# A31L12x register map
Vendor: VENDOR ABOV Semiconductor Co., Ltd.; Series: A31L12x; File version: 1.0
CPU: CM0+ r0p1, little endian, no MPU, no FPU, VTOR, 2 interrupt priority bits
Registers are 32-bit, read-write, reset 0x0 unless marked. A register's access mark holds for its fields unless they carry their own. Offsets are from the block's base; [hi:lo] are bit positions; {n}, {i} and the like mark numbered series.

## SCULV — System Control Unit: LVI and LVR
Base 0x40005100
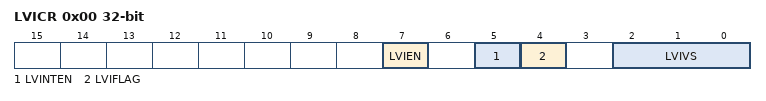
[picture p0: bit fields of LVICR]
0x00 LVICR — Low Voltage Indicator Control Register
  [7] LVIEN — LVI Enable
    0=Disable low voltage indicator; 1=Enable low voltage indicator
  [5] LVINTEN — LVI Interrupt Enable
    0=Disable low voltage indicator interrupt; 1=Enable low voltage indicator interrupt
  [4] LVIFLAG — LVI Interrupt Flag
    0=No request occurred; 1=Request occurred
  [2:0] LVIVS — LVI Voltage Selection
    0=1p75V0 (1.75V); 1=1p75V1 (1.75V); 2=1p90V (1.90V); 3=2p05V (2.05V); 4=2p20V (2.20V); 5=2p35V (2.35V); 6=2p50V (2.50V); 7=2p65V (2.65V)
0x04 LVRCR — Low Voltage Reset Control Register
  [7:0] LVREN — LVR Enable
    85=Disable low voltage reset. (0x55); 0=Enable low voltage reset

## PMU — Power Management Unit
Base 0x40001900
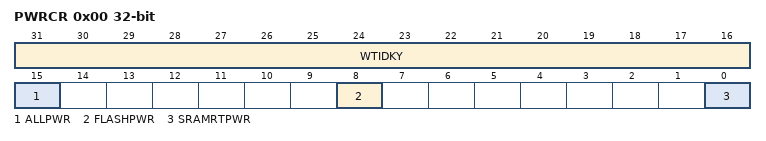
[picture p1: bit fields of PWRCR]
0x00 PWRCR — Power Control Register
  [31:16] WTIDKY wo — Write Identification Key (0x5072)
    0x5072=Value (Key Value (0x5072))
  [15] ALLPWR — All System and Peripheral Except Always-on Regiion Power Control
    0=BySW (Power on/off is controlled by each power control bit); 1=Off (Power off all system and peripheral except always-on region)
  [8] FLASHPWR — Flash Memory Power Control
    0=On (Power On); 1=Off (Power Off)
  [0] SRAMRTPWR — SRAM Retention Power Control
    0=Normal power for SRAM; 1=Retention power for SRAM on sleep and deep sleep mode
{0x40+i} BKR{i} 8-bit (i=0..31) — Back-up Data Register {i}
  [7:0] BACKUP — Back-up Data

## FMC — Flash Memory Controller
Base 0x40001B00
0x00 ADR reset 0x5FFFFF80 — Flash Memory Address Register
  [31:0] ADDR — Flash Memory Address Pointer
0x04 IDR1 — Flash Memory Identification Register 1
  [31:0] ID1 — Flash Memory Identification 0
0x08 IDR2 — Flash Memory Identification Register 2
  [31:0] ID2 — Flash Memory Identification 1
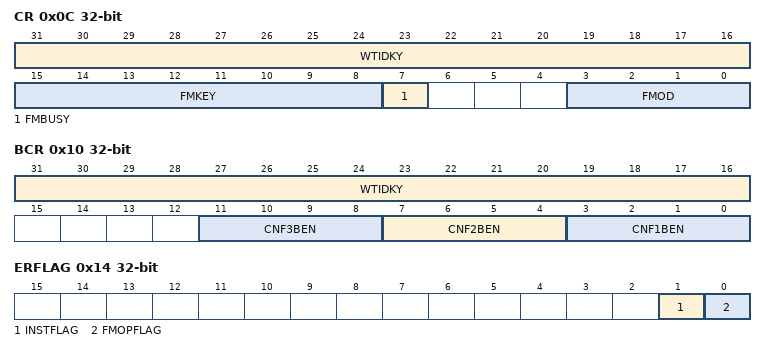
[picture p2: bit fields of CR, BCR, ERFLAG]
0x0C CR — Flash Memory Control Register
  [31:16] WTIDKY wo — Write Identification Key (0x6c93)
    0x6C93=Value (Key Value (0x6c93))
  [15:8] FMKEY — Flash Memory Operation Area Selection
  [7] FMBUSY ro — Flash Memory Operation Mode Busy
  [3:0] FMOD — Flash Memory Operation Mode Selection
0x10 BCR — Flash Memory Configure Area Bulk Erase Control Register
  [31:16] WTIDKY wo — Write Identification Key (0xc1be)
    0xC1BE=Value (Key Value (0xc1be))
  [11:8] CNF3BEN — Configure Option Page 3 Bulk Erase Enable
  [7:4] CNF2BEN — Configure Option Page 2 Bulk Erase Enable
  [3:0] CNF1BEN — Configure Option Page 1 Bulk Erase Enable
0x14 ERFLAG — Flash Memory Error Flag
  [1] INSTFLAG — Don't care
  [0] FMOPFLAG — Error bit of Flash Memory Operation Procedure
0x100 PAGEBUF wo — Flash Memory Page Buffer Area (128bytes/Accessed by 32bit Word Only)

## WDT — Watch-Dog Timer
Base 0x40001A00
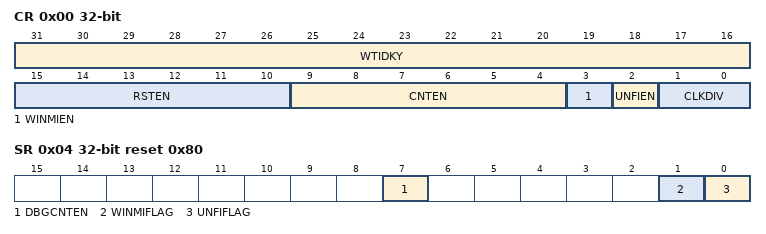
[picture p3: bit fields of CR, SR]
0x00 CR — Watch-Dog Timer Control Register
  [31:16] WTIDKY wo — Write Identification Key (0x5a69)
    0x5A69=Value (Key Value (0x5a69))
  [15:10] RSTEN — Watch-Dog Timer Reset Enable
    37=Disable Watch-Dog Timer reset. (0x25); 0=Enable Watch-Dog Timer reset
  [9:4] CNTEN — Watch-Dog Timer Counter Enable
    26=Disable Watch-Dog Timer counter. (0x1a); 0=Enable Watch-Dog Timer counter
  [3] WINMIEN — Watch-Dog Timer Window Match Interrupt Enable
    0=Disable window data match interrupt; 1=Enable window data match interrupt
  [2] UNFIEN — Watch-Dog Timer Underflow Interrupt Enable
    0=Disable Watch-Dog Timer underflow interrupt; 1=Enable Watch-Dog Timer underflow interrupt
  [1:0] CLKDIV — Watch-Dog Timer Clock Divider
    0=fWDT4; 1=fWDT16; 2=fWDT64; 3=fWDT256
0x04 SR reset 0x80 — Watch-Dog Timer Status Register
  [7] DBGCNTEN — Watch-Dog Timer Counter Enable When the core is halted in debug mode
    0=Run (The Watch-Dog Timer counter continues even if the core is halted); 1=Stop (The Watch-Dog Timer counter is stopped when the core is halted)
  [1] WINMIFLAG — Watch-Dog Timer Window Match Interrupt Flag
    0=No request occurred; 1=Request occurred
  [0] UNFIFLAG — Watch-Dog Timer Underflow Interrupt Flag
    0=No request occurred; 1=Request occurred
0x08 DR reset 0xFFF — Watch-Dog Timer Data Register
  [23:0] DATA — Watch-Dog Timer Data
0x0C CNT ro reset 0xFFF — Watch-Dog Timer Counter Register
  [23:0] CNT — Watch-Dog Timer Counter
0x10 WINDR reset 0x1FFF — Watch-Dog Timer Window Data Register
  [23:0] WDATA — Watch-Dog Timer Window Data
0x14 CNTR wo — Watch-Dog Timer Counter Reload Register
  [7:0] CNTR — Watch-Dog Timer Counter Reload
    106=Reload the WDTDR value to Watch-Dog Timer counter and re-start; 0=NoEffect
